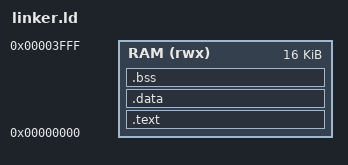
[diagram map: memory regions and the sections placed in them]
ENTRY(_start)

MEMORY
{
    RAM (rwx) : ORIGIN = 0x00000000, LENGTH = 16K
}

SECTIONS
{
    .text : {
        *(.text*)
        *(.rodata*)
    } > RAM

    .data : {
        *(.data*)
    } > RAM

    .bss : {
        *(.bss*)
        *(COMMON)
    } > RAM

    . = ALIGN(4);

    _stack_top = ORIGIN(RAM) + LENGTH(RAM);
}
